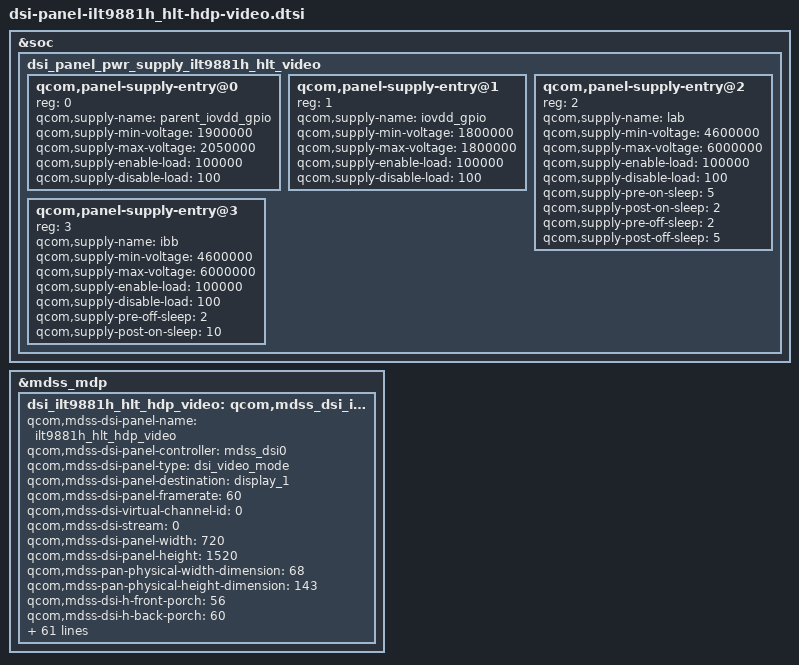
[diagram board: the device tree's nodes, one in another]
/***********************************************************
** Copyright (C), 2008-2016, OPPO Mobile Comm Corp., Ltd.
** ODM_WT_EDIT
** File: - panel_ilt9881h_hlt_hdp_video.h
** Description: source ilt9881h hlt panel config in kernel
**
** Version: 1.0
** Date : 2018/05/17
**
** ------------------------------- Revision History: -------------------------------
**  	<author>		<data> 	   <version >	       <desc>
**
****************************************************************/
&soc {
	dsi_panel_pwr_supply_ilt9881h_hlt_video: dsi_panel_pwr_supply_ilt9881h_hlt_video {
		#address-cells = <1>;
		#size-cells = <0>;
		qcom,panel-supply-entry@0 {
			reg = <0>;
			qcom,supply-name = "parent_iovdd_gpio";
			qcom,supply-min-voltage = <1900000>;
			qcom,supply-max-voltage = <2050000>;
			qcom,supply-enable-load = <100000>;
			qcom,supply-disable-load = <100>;
		};
		qcom,panel-supply-entry@1 {
			reg = <1>;
			qcom,supply-name = "iovdd_gpio";
			qcom,supply-min-voltage = <1800000>;
			qcom,supply-max-voltage = <1800000>;
			qcom,supply-enable-load = <100000>;
			qcom,supply-disable-load = <100>;
		};
		qcom,panel-supply-entry@2 {
			reg = <2>;
			qcom,supply-name = "lab";
			qcom,supply-min-voltage = <4600000>;
			qcom,supply-max-voltage = <6000000>;
			qcom,supply-enable-load = <100000>;
			qcom,supply-disable-load = <100>;
			qcom,supply-pre-on-sleep = <5>;
			qcom,supply-post-on-sleep = <2>;
			qcom,supply-pre-off-sleep = <2>;
			qcom,supply-post-off-sleep = <5>;
		};
		qcom,panel-supply-entry@3 {
			reg = <3>;
			qcom,supply-name = "ibb";
			qcom,supply-min-voltage = <4600000>;
			qcom,supply-max-voltage = <6000000>;
			qcom,supply-enable-load = <100000>;
			qcom,supply-disable-load = <100>;
			qcom,supply-pre-off-sleep = <2>;
			qcom,supply-post-on-sleep = <10>;
		};
	};
};
&mdss_mdp {
	dsi_ilt9881h_hlt_hdp_video: qcom,mdss_dsi_ilt9881h_hlt_hdp_video {
		qcom,mdss-dsi-panel-name = "ilt9881h_hlt_hdp_video";
		qcom,mdss-dsi-panel-controller = <&mdss_dsi0>;
		qcom,mdss-dsi-panel-type = "dsi_video_mode";
		qcom,mdss-dsi-panel-destination = "display_1";
		qcom,mdss-dsi-panel-framerate = <60>;
		qcom,mdss-dsi-virtual-channel-id = <0>;
		qcom,mdss-dsi-stream = <0>;
		qcom,mdss-dsi-panel-width = <720>;
		qcom,mdss-dsi-panel-height = <1520>;
		qcom,mdss-pan-physical-width-dimension = <68>;
		qcom,mdss-pan-physical-height-dimension = <143>;
		qcom,mdss-dsi-h-front-porch = <56>;
		qcom,mdss-dsi-h-back-porch = <60>;
		qcom,mdss-dsi-h-pulse-width = <4>;
		qcom,mdss-dsi-h-sync-skew = <0>;
		qcom,mdss-dsi-v-back-porch = <24>;
		qcom,mdss-dsi-v-front-porch = <240>;
		qcom,mdss-dsi-v-pulse-width = <4>;
		qcom,mdss-dsi-h-left-border = <0>;
		qcom,mdss-dsi-h-right-border = <0>;
		qcom,mdss-dsi-v-top-border = <0>;
		qcom,mdss-dsi-v-bottom-border = <0>;
		qcom,mdss-dsi-bpp = <24>;
		qcom,mdss-dsi-color-order = "rgb_swap_rgb";
		qcom,mdss-dsi-underflow-color = <0xff>;
		qcom,mdss-dsi-border-color = <0>;
		qcom,mdss-dsi-on-command = [
			39 01 00 00 00 00 04 FF 98 81 01
			39 01 00 00 00 00 02 00 48
			39 01 00 00 00 00 02 01 33
			39 01 00 00 00 00 02 02 FF
			39 01 00 00 00 00 02 03 05
			39 01 00 00 00 00 02 08 86
			39 01 00 00 00 00 02 09 01
			39 01 00 00 00 00 02 0a 73
			39 01 00 00 00 00 02 0b 00
			39 01 00 00 00 00 02 0c FF
			39 01 00 00 00 00 02 0d FF
			39 01 00 00 00 00 02 0e 05
			39 01 00 00 00 00 02 0f 05
			39 01 00 00 00 00 02 28 48
			39 01 00 00 00 00 02 29 86
			39 01 00 00 00 00 02 31 07
			39 01 00 00 00 00 02 32 07
			39 01 00 00 00 00 02 33 00
			39 01 00 00 00 00 02 34 2A
			39 01 00 00 00 00 02 35 09
			39 01 00 00 00 00 02 36 0B
			39 01 00 00 00 00 02 37 01
			39 01 00 00 00 00 02 38 06
			39 01 00 00 00 00 02 39 15
			39 01 00 00 00 00 02 3a 17
			39 01 00 00 00 00 02 3b 11
			39 01 00 00 00 00 02 3c 13
			39 01 00 00 00 00 02 3d 07
			39 01 00 00 00 00 02 3e 07
			39 01 00 00 00 00 02 3f 07
			39 01 00 00 00 00 02 40 07
			39 01 00 00 00 00 02 41 07
			39 01 00 00 00 00 02 42 07
			39 01 00 00 00 00 02 43 07
			39 01 00 00 00 00 02 44 07
			39 01 00 00 00 00 02 45 07
			39 01 00 00 00 00 02 46 07
			39 01 00 00 00 00 02 47 07
			39 01 00 00 00 00 02 48 07
			39 01 00 00 00 00 02 49 00
			39 01 00 00 00 00 02 4a 2A
			39 01 00 00 00 00 02 4b 08
			39 01 00 00 00 00 02 4c 0A
			39 01 00 00 00 00 02 4d 01
			39 01 00 00 00 00 02 4e 06
			39 01 00 00 00 00 02 4f 14
			39 01 00 00 00 00 02 50 16
			39 01 00 00 00 00 02 51 10
			39 01 00 00 00 00 02 52 12
			39 01 00 00 00 00 02 53 07
			39 01 00 00 00 00 02 54 07
			39 01 00 00 00 00 02 55 07
			39 01 00 00 00 00 02 56 07
			39 01 00 00 00 00 02 57 07
			39 01 00 00 00 00 02 58 07
			39 01 00 00 00 00 02 59 07
			39 01 00 00 00 00 02 5a 07
			39 01 00 00 00 00 02 5b 07
			39 01 00 00 00 00 02 5c 07
			39 01 00 00 00 00 02 61 07
			39 01 00 00 00 00 02 62 07
			39 01 00 00 00 00 02 63 00
			39 01 00 00 00 00 02 64 2a
			39 01 00 00 00 00 02 65 0a
			39 01 00 00 00 00 02 66 08
			39 01 00 00 00 00 02 67 16
			39 01 00 00 00 00 02 68 14
			39 01 00 00 00 00 02 69 12
			39 01 00 00 00 00 02 6a 10
			39 01 00 00 00 00 02 6b 06
			39 01 00 00 00 00 02 6c 01
			39 01 00 00 00 00 02 6d 07
			39 01 00 00 00 00 02 6e 07
			39 01 00 00 00 00 02 6f 07
			39 01 00 00 00 00 02 70 07
			39 01 00 00 00 00 02 71 07
			39 01 00 00 00 00 02 72 07
			39 01 00 00 00 00 02 73 07
			39 01 00 00 00 00 02 74 07
			39 01 00 00 00 00 02 75 07
			39 01 00 00 00 00 02 76 07
			39 01 00 00 00 00 02 77 07
			39 01 00 00 00 00 02 78 07
			39 01 00 00 00 00 02 79 00
			39 01 00 00 00 00 02 7a 2a
			39 01 00 00 00 00 02 7b 0b
			39 01 00 00 00 00 02 7c 09
			39 01 00 00 00 00 02 7d 17
			39 01 00 00 00 00 02 7e 15
			39 01 00 00 00 00 02 7f 13
			39 01 00 00 00 00 02 80 11
			39 01 00 00 00 00 02 81 06
			39 01 00 00 00 00 02 82 01
			39 01 00 00 00 00 02 83 07
			39 01 00 00 00 00 02 84 07
			39 01 00 00 00 00 02 85 07
			39 01 00 00 00 00 02 86 07
			39 01 00 00 00 00 02 87 07
			39 01 00 00 00 00 02 88 07
			39 01 00 00 00 00 02 89 07
			39 01 00 00 00 00 02 8a 07
			39 01 00 00 00 00 02 8b 07
			39 01 00 00 00 00 02 8c 07
			39 01 00 00 00 00 02 d0 01
			39 01 00 00 00 00 02 d1 00
			39 01 00 00 00 00 02 e2 00
			39 01 00 00 00 00 02 e6 22
			39 01 00 00 00 00 02 e7 54
			39 01 00 00 00 00 02 B0 33
			39 01 00 00 00 00 02 B1 33
			39 01 00 00 00 00 02 B2 00
			39 01 00 00 00 00 02 E7 54
			39 01 00 00 00 00 04 FF 98 81 02
			39 01 00 00 00 00 02 4B 5A
			39 01 00 00 00 00 02 4D 4E
			39 01 00 00 00 00 02 1A 48
			39 01 00 00 00 00 02 4D 4E
			39 01 00 00 00 00 02 4E 00
			39 01 00 00 00 00 02 1A 48
			39 01 00 00 00 00 02 70 34
			39 01 00 00 00 00 02 73 0A
			39 01 00 00 00 00 02 79 06
			39 01 00 00 00 00 04 FF 98 81 05
			39 01 00 00 00 00 02 03 01
			39 01 00 00 00 00 02 04 25
			39 01 00 00 00 00 02 58 63
			39 01 00 00 00 00 02 5D 07
			39 01 00 00 00 00 02 63 A1
			39 01 00 00 00 00 02 64 8D
			39 01 00 00 00 00 02 68 6B
			39 01 00 00 00 00 02 69 7F
			39 01 00 00 00 00 02 6A DD
			39 01 00 00 00 00 02 6B BB
			39 01 00 00 00 00 04 FF 98 81 06
			39 01 00 00 00 00 02 11 03
			39 01 00 00 00 00 02 13 4D
			39 01 00 00 00 00 02 14 41
			39 01 00 00 00 00 02 15 F9
			39 01 00 00 00 00 02 16 40
			39 01 00 00 00 00 02 17 48
			39 01 00 00 00 00 02 18 3B
			39 01 00 00 00 00 02 D6 85
			39 01 00 00 00 00 02 27 20
			39 01 00 00 00 00 02 28 20
			39 01 00 00 00 00 02 2E 01
			39 01 00 00 00 00 02 C0 F7
			39 01 00 00 00 00 02 C1 02
			39 01 00 00 00 00 02 C2 04
			39 01 00 00 00 00 02 48 0F
			39 01 00 00 00 00 02 4D 80
			39 01 00 00 00 00 02 4E 40
			39 01 00 00 00 00 02 7C 40
			39 01 00 00 00 00 02 C7 05
			39 01 00 00 00 00 04 FF 98 81 07
			39 01 00 00 00 00 02 0F 02
			39 01 00 00 00 00 04 FF 98 81 08
			39 01 00 00 00 00 1C E0 00 24 4C 6D 9F 50 CD F4 24 4D 95 90 C7 F9 2A AA 5C 98 BE EC FF 12 42 7B A9 03 EC
			39 01 00 00 00 00 1C E1 00 24 4C 6D 9F 50 CD F4 24 4D 95 90 C7 F9 2A AA 5C 98 BE EC FF 12 42 7B A9 03 EC
			39 01 00 00 00 00 04 FF 98 81 0E
			39 01 00 00 00 00 02 00 A0
			39 01 00 00 00 00 02 43 60
			39 01 00 00 00 00 02 01 28
			39 01 00 00 00 00 02 02 09
			39 01 00 00 00 00 02 13 05
			39 01 00 00 00 00 02 20 07
			39 01 00 00 00 00 02 29 BE
			39 01 00 00 00 00 02 25 0A
			39 01 00 00 00 00 02 26 38
			39 01 00 00 00 00 02 2D 98
			39 01 00 00 00 00 02 40 07
			39 01 00 00 00 00 02 49 BE
			39 01 00 00 00 00 02 45 0B
			39 01 00 00 00 00 02 46 B7
			39 01 00 00 00 00 02 4D 96
			39 01 00 00 00 00 04 FF 98 81 0E
			39 01 00 00 00 00 02 C0 11
			39 01 00 00 00 00 02 C1 80
			39 01 00 00 00 00 02 C2 08
			39 01 00 00 00 00 02 C3 01
			39 01 00 00 00 00 02 C4 44
			39 01 00 00 00 00 02 C5 44
			39 01 00 00 00 00 02 C6 44
			39 01 00 00 00 00 02 C7 40
			39 01 00 00 00 00 02 D0 23
			39 01 00 00 00 00 02 D1 00
			39 01 00 00 00 00 02 D2 00
			39 01 00 00 00 00 02 D3 95
			39 01 00 00 00 00 02 D4 95
			39 01 00 00 00 00 02 D5 95
			39 01 00 00 00 00 02 D6 95
			39 01 00 00 00 00 02 D7 95
			39 01 00 00 00 00 02 D8 95
			39 01 00 00 00 00 02 D9 95
			39 01 00 00 00 00 02 DA 11
			39 01 00 00 00 00 02 DB 44
			39 01 00 00 00 00 02 DC 44
			39 01 00 00 00 00 02 DD 44
			39 01 00 00 00 00 02 E1 08
			39 01 00 00 00 00 02 E2 19
			39 01 00 00 00 00 02 E3 10
			39 01 00 00 00 00 04 FF 98 81 0E
			39 01 00 00 00 00 02 05 00
			39 01 00 00 00 00 02 07 21
			39 01 00 00 00 00 02 4B 1A
			39 01 00 00 00 00 04 FF 98 81 0C
			39 01 00 00 00 00 02 00 12
			39 01 00 00 00 00 02 01 42
			39 01 00 00 00 00 02 02 13
			39 01 00 00 00 00 02 03 4A
			39 01 00 00 00 00 02 04 14
			39 01 00 00 00 00 02 05 54
			39 01 00 00 00 00 02 06 14
			39 01 00 00 00 00 02 07 5C
			39 01 00 00 00 00 02 08 13
			39 01 00 00 00 00 02 09 53
			39 01 00 00 00 00 02 0A 12
			39 01 00 00 00 00 02 0B 49
			39 01 00 00 00 00 02 0C 12
			39 01 00 00 00 00 02 0D 43
			39 01 00 00 00 00 02 0E 13
			39 01 00 00 00 00 02 0F 4B
			39 01 00 00 00 00 02 10 14
			39 01 00 00 00 00 02 11 55
			39 01 00 00 00 00 02 12 14
			39 01 00 00 00 00 02 13 5A
			39 01 00 00 00 00 02 14 13
			39 01 00 00 00 00 02 15 4F
			39 01 00 00 00 00 02 16 12
			39 01 00 00 00 00 02 17 46
			39 01 00 00 00 00 02 18 13
			39 01 00 00 00 00 02 19 4D
			39 01 00 00 00 00 02 1A 14
			39 01 00 00 00 00 02 1B 57
			39 01 00 00 00 00 02 1C 14
			39 01 00 00 00 00 02 1D 5B
			39 01 00 00 00 00 02 1E 13
			39 01 00 00 00 00 02 1F 51
			39 01 00 00 00 00 02 20 12
			39 01 00 00 00 00 02 21 47
			39 01 00 00 00 00 02 22 13
			39 01 00 00 00 00 02 23 4E
			39 01 00 00 00 00 02 24 14
			39 01 00 00 00 00 02 25 58
			39 01 00 00 00 00 02 26 13
			39 01 00 00 00 00 02 27 52
			39 01 00 00 00 00 02 28 12
			39 01 00 00 00 00 02 29 44
			39 01 00 00 00 00 02 2A 13
			39 01 00 00 00 00 02 2B 4C
			39 01 00 00 00 00 02 2C 14
			39 01 00 00 00 00 02 2D 59
			39 01 00 00 00 00 02 2E 13
			39 01 00 00 00 00 02 2F 50
			39 01 00 00 00 00 02 30 12
			39 01 00 00 00 00 02 31 45
			39 01 00 00 00 00 02 32 14
			39 01 00 00 00 00 02 33 56
			39 01 00 00 00 00 02 34 12
			39 01 00 00 00 00 02 35 48
			39 01 00 00 00 00 04 FF 98 81 06
			39 01 00 00 00 00 02 06 C4
			39 01 00 00 00 00 02 7C 40 // 3 lane
			39 01 00 00 00 00 02 DD 10 // 3 lane
			39 01 00 00 00 00 04 FF 98 81 03
			39 01 00 00 00 00 02 83 30
			39 01 00 00 00 00 02 84 00
			//UI mode
			39 01 00 00 00 00 04 FF 98 81 03
			39 01 00 00 00 00 02 90 14
			39 01 00 00 00 00 02 91 F6
			39 01 00 00 00 00 02 92 16
			//still mode
			39 01 00 00 00 00 02 94 0F
			39 01 00 00 00 00 02 95 0F
			39 01 00 00 00 00 02 96 10
			39 01 00 00 00 00 02 97 10
			39 01 00 00 00 00 02 98 0E
			39 01 00 00 00 00 02 99 0F
			39 01 00 00 00 00 02 9A 0F
			39 01 00 00 00 00 02 9B 10
			//moving mode
			39 01 00 00 00 00 02 9E 01
			39 01 00 00 00 00 02 A1 0A
			39 01 00 00 00 00 02 A2 0A
			39 01 00 00 00 00 02 A3 0B
			39 01 00 00 00 00 02 A4 0D
			39 01 00 00 00 00 02 A5 0E
			39 01 00 00 00 00 04 FF 98 81 00
			29 01 00 00 00 00 03 68 04 00
			39 01 00 00 00 00 03 51 00 00
			39 01 00 00 00 00 02 53 24
			//add cabc default mode ui mode
			39 01 00 00 00 00 04 FF 98 81 03
			39 01 00 00 00 00 02 AC FA
			39 01 00 00 00 00 04 FF 98 81 00
			39 01 00 00 00 00 02 55 01
			05 01 00 00 78 00 02 11 00
			05 01 00 00 32 00 02 29 00
			39 01 00 00 00 00 02 35 00];

		qcom,mdss-dsi-off-command = [
			39 01 00 00 00 00 04 FF 98 81 00
			05 01 00 00 14 00 02 28 00
			05 01 00 00 78 00 02 10 00
			39 01 00 00 00 00 04 FF 98 81 0F];
		qcom,mdss-dsi-on-command-state = "dsi_lp_mode";
		qcom,mdss-dsi-off-command-state = "dsi_lp_mode";
		qcom,vddio-always-on-enabled;
		qcom,mdss-dsi-h-sync-pulse = <1>;
		qcom,mdss-dsi-traffic-mode = "burst_mode";
		qcom,panel-supply-entries = <&dsi_panel_pwr_supply_ilt9881h_hlt_video>;
		//qcom,panel-supply-entries = <&dsi_panel_pwr_supply>;
		//qcom,mdss-dsi-lane-map = "lane_map_0123";
		qcom,mdss-dsi-bllp-eof-power-mode;
		qcom,mdss-dsi-bllp-power-mode;
		qcom,mdss-dsi-lane-0-state;
		qcom,mdss-dsi-lane-1-state;
		qcom,mdss-dsi-lane-2-state;
		//qcom,mdss-dsi-lane-3-state;
		//qcom,mdss-dsi-panel-timings = [FB 38 26 00 6A 6C 2C 3C 2F 03 04 00];
		qcom,mdss-dsi-panel-timings-phy-v2 = [22 1D 07 08 04 03 04 A0
		22 1D 07 08 04 03 04 A0
		22 1D 07 08 04 03 04 A0
		22 1D 07 08 04 03 04 A0
		22 16 06 07 04 03 04 A0];
		qcom,mdss-dsi-t-clk-post = <0x0C>;
		qcom,mdss-dsi-t-clk-pre = <0x29>;
		qcom,mdss-dsi-bl-pmic-control-type = "bl_ctrl_dcs";
		qcom,mdss-dsi-bl-min-level = <1>;
		qcom,mdss-dsi-bl-max-level = <2047>;
		qcom,mdss-brightness-max-level = <2047>;
		qcom,blmap-size = <128>;
		qcom,blmap = <
			36 160
			16 223
			17 217
			19 202
			19 200
			20 178
			22 154
			22 147
			24 107
			24 89
			26 45
			27 0
			29 94
			29 95
			30 140
			33 256
			34 304
			36 443
			37 491
			40 654
			40 697
			43 883
			46 1091
			47 1127
			50 1359
			53 1617
			53 1634
			60 2209
			60 2230
			64 2570
			63 2552
			71 3341
			71 3319
			75 3751
			80 4221
			84 4733
			89 5290
			88 5181
			99 6530
			98 6402
			103 7077
			117 8786
			115 8624
			122 9477
			128 10396
			135 11387
			132 11025
			149 13556
			157 14788
			166 16114
			163 15631
			183 19005
			180 18449
			203 22329
			199 21691
			209 23447
			236 28211
			232 27428
			243 29580
			255 31880
			268 34335
			282 36965
			317 44054
			176 15600>;
		qcom,mdss-dsi-dma-trigger = "trigger_sw";
		qcom,mdss-dsi-mdp-trigger = "none";
		qcom,mdss-dsi-lp11-init;
		//qcom,mdss-dsi-init-delay-us = <50000>;
		qcom,mdss-dsi-reset-sequence = <1 10>, <0 10>, <1 5>;
		qcom,esd-check-enabled;
		qcom,mdss-dsi-panel-status-command = [06 01 00 01 00 00 01 0a];
		qcom,mdss-dsi-panel-status-command-state = "dsi_lp_mode";
		qcom,mdss-dsi-panel-status-read-length = <1>;
		qcom,mdss-dsi-panel-status-value = <0x9C>;
		qcom,mdss-dsi-panel-status-check-mode = "reg_read";
		qcom,mdss-dsi-tx-eot-append;
		//qcom,mdss-dsi-post-init-delay = <1>;
		qcom,mdss-dsi-cabc-ui-command = [
		39 01 00 00 00 00 04 FF 98 81 03
		39 01 00 00 00 00 02 AC FA
		39 01 00 00 00 00 04 FF 98 81 00
		39 01 00 00 00 00 02 55 01];

		qcom,mdss-dsi-cabc-image-command = [
		39 01 00 00 00 00 04 FF 98 81 03
		39 01 00 00 00 00 02 AC E5
		39 01 00 00 00 00 04 FF 98 81 00
		39 01 00 00 00 00 02 55 02];

		qcom,mdss-dsi-cabc-video-command = [
		39 01 00 00 00 00 04 FF 98 81 03
		39 01 00 00 00 00 02 AC D5
		39 01 00 00 00 00 04 FF 98 81 00
		39 01 00 00 00 00 02 55 03];
	};
};

